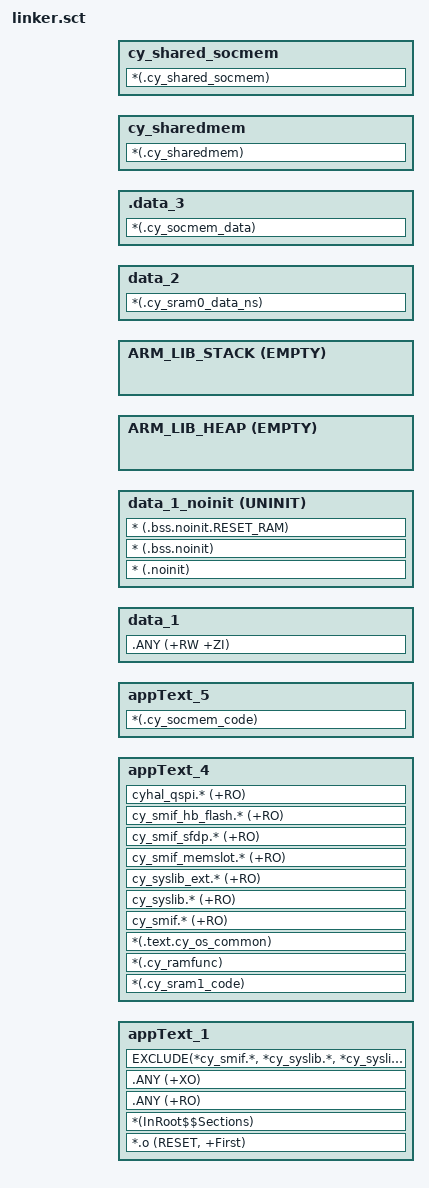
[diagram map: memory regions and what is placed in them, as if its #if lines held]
#! armclang -E --target=arm-arm-none-eabi -mcpu=cortex-m33 -xc
; command above MUST be in first line (no comment above!)
/***************************************************************************//**
* \file pse84_ns_flash.sct
* \version 1.0.0
*
* scatter file for the armclang C compiler.
*
* The main purpose of this file is to describe how the sections in the
* input files should be mapped into the output file, and to control the memory
* layout of the output file.
*
* \note The entry point location starts at 0x14000000. The valid
* application image should be placed there.
*
* \note The linker files included with the PDL template projects must be generic
* and handle all common use cases. Your project may not use every section
* defined in the linker files. In that case you may see warnings during the
* build process. In your project, you can simply comment out or remove the
* relevant code in the linker file.
*
********************************************************************************
* \copyright
* Copyright (c) (2020-2023), Cypress Semiconductor Corporation (an Infineon company) or
* an affiliate of Cypress Semiconductor Corporation.
* SPDX-License-Identifier: Apache-2.0
*
* Licensed under the Apache License, Version 2.0 (the "License");
* you may not use this file except in compliance with the License.
* You may obtain a copy of the License at
*
*     http://www.apache.org/licenses/LICENSE-2.0
*
* Unless required by applicable law or agreed to in writing, software
* distributed under the License is distributed on an "AS IS" BASIS,
* WITHOUT WARRANTIES OR CONDITIONS OF ANY KIND, either express or implied.
* See the License for the specific language governing permissions and
* limitations under the License.
*******************************************************************************/
#include "pse84_common.h"

/* To set stack size in application add makefile ldflags: --predefine="-DAPP_MSP_STACK_SIZE=0x2000" */
#ifdef APP_MSP_STACK_SIZE
#define __STACK_SIZE    APP_MSP_STACK_SIZE
#else
#define __STACK_SIZE    MSP_STACK_SIZE
#endif

#define CODE_XIP0_OFFSET            XIP0_CM33NS_APP_OFFSET
#define CODE_XIP0_VMA               XIP0_NS_CBUS_START + CODE_XIP0_OFFSET
#define CODE_XIP0_LMA               XIP0_NS_SAHB_START + CODE_XIP0_OFFSET
#define CODE_XIP0_SIZE              XIP0_CM33NS_APP_SIZE

#define CODE_RRAM_OFFSET            RRAM_CM33NS_APP_OFFSET
#define CODE_RRAM_VMA               RRAM_NVM_MAIN_NS_CBUS_START + CODE_RRAM_OFFSET
#define CODE_RRAM_LMA               RRAM_NVM_MAIN_NS_START + CODE_RRAM_OFFSET
#define CODE_RRAM_SIZE              RRAM_CM33NS_APP_SIZE

#define CODE_SRAM0_OFFSET           SRAM0_CM33NS_APP_OFFSET
#define CODE_SRAM0_VMA              SRAM0_NS_CBUS_START + CODE_SRAM0_OFFSET
#define CODE_SRAM0_LMA              SRAM0_NS_SAHB_START + CODE_SRAM0_OFFSET
#define CODE_SRAM0_SIZE             SRAM0_CM33NS_APP_SIZE

#define CODE_SRAM1_OFFSET           SRAM1_CM33NS_APP_OFFSET
#define CODE_SRAM1_VMA              SRAM1_NS_CBUS_START + CODE_SRAM1_OFFSET
#define CODE_SRAM1_LMA              SRAM1_NS_SAHB_START + CODE_SRAM1_OFFSET
#define CODE_SRAM1_SIZE             SRAM1_CM33NS_APP_SIZE

#define CODE_SOCMEMSRAM_OFFSET      SOCMEMSRAM_CM33NS_APP_OFFSET
#define CODE_SOCMEMSRAM_VMA         SOCMEMSRAM_NS_CBUS_START + CODE_SOCMEMSRAM_OFFSET
#define CODE_SOCMEMSRAM_LMA         SOCMEMSRAM_NS_SAHB_START + CODE_SOCMEMSRAM_OFFSET
#define CODE_SOCMEMSRAM_SIZE        SOCMEMSRAM_CM33NS_APP_SIZE

#define DATA_SRAM0_OFFSET           SRAM0_CM33NS_DATA_OFFSET
#define DATA_SRAM0_VMA              SRAM0_NS_SAHB_START + DATA_SRAM0_OFFSET
#define DATA_SRAM0_LMA              SRAM0_NS_SAHB_START + DATA_SRAM0_OFFSET
#define DATA_SRAM0_SIZE             SRAM0_CM33NS_DATA_SIZE

#define  DATA_SRAM1_OFFSET           SRAM1_CM33NS_DATA_OFFSET
#define  DATA_SRAM1_VMA              SRAM1_NS_SAHB_START + DATA_SRAM1_OFFSET
#define  DATA_SRAM1_LMA              SRAM1_NS_SAHB_START + DATA_SRAM1_OFFSET
#define  DATA_SRAM1_SIZE             (SRAM1_CM33NS_DATA_SIZE - SRAM0_SHARED_SIZE)

#define  DATA_SOCMEMSRAM_OFFSET      SOCMEMSRAM_CM33NS_DATA_OFFSET
#define  DATA_SOCMEMSRAM_VMA         SOCMEMSRAM_NS_SAHB_START + DATA_SOCMEMSRAM_OFFSET
#define  DATA_SOCMEMSRAM_LMA         SOCMEMSRAM_NS_SAHB_START + DATA_SOCMEMSRAM_OFFSET
#define  DATA_SOCMEMSRAM_SIZE        SOCMEMSRAM_CM33NS_DATA_SIZE

#define SOCMEMSRAM_SHARED_LMA       (SOCMEMSRAM_NS_SAHB_START + SOCMEMSRAM_SHARED_OFFSET)

#define SRAM0_SHARED_CM33_SIZE      SRAM0_SHARED_SIZE - SRAM0_SHARED_CM0_SIZE
#define SRAM0_SHARED_LMA            SRAM0_S_SAHB_START + SRAM0_SIZE - SRAM0_SHARED_CM33_SIZE
#define SRAM1_SHARED_LMA            (SRAM1_NS_SAHB_START + SRAM1_SIZE - SRAM1_SHARED_SIZE) + SRAM1_SHARED_CM33S_SIZE

#define  RAMVECTORS_ALIGNMENT        CM33_RAMVECTORS_ALIGNMENT
/*-----------------------------------------------------------------------------------*/
/* Modify the following values according to the memory in which the code needs to go */
/* E.g. CODE_1_VMA should always point to the memory in which the main code sits.    */
/* If main code needs to reside in externl flash then set it to CODE_XIP0_VMA        */
/*-----------------------------------------------------------------------------------*/

#define CODE_1_VMA                  CODE_XIP0_VMA
#define CODE_1_LMA                  CODE_XIP0_LMA
#define CODE_1_SIZE                 CODE_XIP0_SIZE

#define CODE_2_VMA                  CODE_RRAM_VMA
#define CODE_2_LMA                  CODE_RRAM_LMA
#define CODE_2_SIZE                 CODE_RRAM_SIZE

#define CODE_4_VMA                  CODE_SRAM1_VMA
#define CODE_4_LMA                  CODE_SRAM1_LMA
#define CODE_4_SIZE                 CODE_SRAM1_SIZE

#define CODE_3_VMA                  CODE_SRAM0_VMA
#define CODE_3_LMA                  CODE_SRAM0_LMA
#define CODE_3_SIZE                 CODE_SRAM0_SIZE

#define CODE_5_VMA                  CODE_SOCMEMSRAM_VMA
#define CODE_5_LMA                  CODE_SOCMEMSRAM_LMA
#define CODE_5_SIZE                 CODE_SOCMEMSRAM_SIZE

#define DATA_2_VMA                  DATA_SRAM0_VMA
#define DATA_2_LMA                  DATA_SRAM0_LMA
#define DATA_2_SIZE                 DATA_SRAM0_SIZE

#define DATA_1_VMA                  DATA_SRAM1_VMA
#define DATA_1_LMA                  DATA_SRAM1_LMA
#define DATA_1_SIZE                 DATA_SRAM1_SIZE

#define DATA_3_VMA                  DATA_SOCMEMSRAM_VMA
#define DATA_3_LMA                  DATA_SOCMEMSRAM_LMA
#define DATA_3_SIZE                 DATA_SOCMEMSRAM_SIZE

#define SHARED_MEM0_LMA             SRAM1_SHARED_LMA
#define SHARED_MEM0_VMA             SRAM1_SHARED_LMA
#define SHARED_MEM0_SIZE            SRAM1_SHARED_SIZE

#define SHARED_MEM1_LMA             SOCMEMSRAM_SHARED_LMA
#define SHARED_MEM1_VMA             SOCMEMSRAM_SHARED_LMA
#define SHARED_MEM1_SIZE            SOCMEMSRAM_SHARED_SIZE

/* only for xip code  we will use CBUS */

#define __app_text1_vma__           CODE_1_VMA

#define __app_text2_vma__           CODE_2_LMA

#define __app_text3_vma__           CODE_3_LMA

#define __app_text4_vma__           CODE_4_LMA

#define __app_text5_vma__           CODE_5_LMA

#define __data1_vma__               DATA_1_VMA
#define __data2_vma__               DATA_2_VMA
#define __data3_vma__               DATA_3_VMA

/*
;------------- <<< end of configuration section >>> ---------------------------
*/

/*----------------------------------------------------------------------------
  User Stack & Heap boundary definition
 *----------------------------------------------------------------------------*/
#define __STACK_TOP    (DATA_1_VMA + DATA_1_SIZE)    /* starts at end of DATA_1 */
#define __HEAP_BASE    (AlignExpr(+0, 8))           /* starts after DATA_1 section, 8 byte aligned */
#define __HEAP_END    (__STACK_TOP - __STACK_SIZE)
#define __HEAP_SIZE   (__HEAP_END - __HEAP_BASE)

/*----------------------------------------------------------------------------
  Scatter File Definitions definition
 *----------------------------------------------------------------------------*/

#define __app_text1_vma__ CODE_1_VMA
#define __app_text1_lma__ CODE_1_VMA
  /* Below check is redundant as linker thorws error. Just kept it for reference */
  /* ScatterAssert(2*XIP0_SECTOR_SIZE <= XIP0_CM33S_SLOT_SIZE); */ /* CM33 S Image can't fit in the slot. Increase the slot size XIP0_CM33S_SLOT_SIZE */

  lr_app_text1 __app_text1_lma__  CODE_1_SIZE  {       ; load region size_region
    appText_1 __app_text1_vma__ CODE_1_SIZE  {         ; load address = execution address
    *.o (RESET, +First)
    *(InRoot$$Sections)
;   *(Veneer$$CMSE)                           ; uncomment for secure applications
    .ANY (+RO)
    .ANY (+XO)
    EXCLUDE(*cy_smif.*, *cy_syslib.*, *cy_syslib_ext.*, *cy_smif_memslot.*, *cy_smif_sfdp.*, *cy_smif_hb_flash.*, *cyhal_qspi.*)
    }
/*
    appText_2 __app_text2_vma__ CODE_2_SIZE {
    }

    appText_3 __app_text3_vma__ {
    }
*/
    appText_4 __app_text4_vma__ {
      *(.cy_sram1_code)
      *(.cy_ramfunc)
      *(.text.cy_os_common)
      cy_smif.* (+RO)
      cy_syslib.* (+RO)
      cy_syslib_ext.* (+RO)
      cy_smif_memslot.* (+RO)
      cy_smif_sfdp.* (+RO)
      cy_smif_hb_flash.* (+RO)
      cyhal_qspi.* (+RO)
    }

    appText_5 __app_text5_vma__ {
      *(.cy_socmem_code)
    }

    data_1 __data1_vma__ DATA_1_SIZE  {  ; RW data
      .ANY (+RW +ZI)
    }

    ; Place variables in the section that should not be initialized during the
    ; device startup.
    data_1_noinit +0 UNINIT
    {
        * (.noinit)
		* (.bss.noinit)
        * (.bss.noinit.RESET_RAM)
    }

    ARM_LIB_HEAP  __HEAP_BASE EMPTY  __HEAP_SIZE  {   ; Reserve empty region for heap
    }

    ARM_LIB_STACK __STACK_TOP EMPTY -__STACK_SIZE {   ; Reserve empty region for stack
    }

    data_2 __data2_vma__ {
      *(.cy_sram0_data_ns)
    }

    .data_3 __data3_vma__ {
      *(.cy_socmem_data)
    }
    cy_sharedmem SHARED_MEM0_LMA SHARED_MEM0_SIZE {
      *(.cy_sharedmem)
    }
    cy_shared_socmem SHARED_MEM1_LMA SHARED_MEM1_SIZE {
      *(.cy_shared_socmem)
    }
  }
